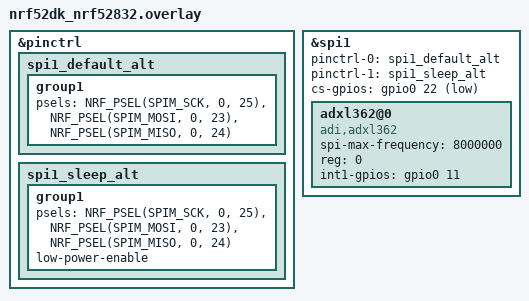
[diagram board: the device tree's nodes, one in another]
/*
 * Copyright (c) 2019 Nordic Semiconductor ASA
 *
 * SPDX-License-Identifier: Apache-2.0
 */

&pinctrl {
	spi1_default_alt: spi1_default_alt {
		group1 {
			psels = <NRF_PSEL(SPIM_SCK, 0, 25)>,
				<NRF_PSEL(SPIM_MOSI, 0, 23)>,
				<NRF_PSEL(SPIM_MISO, 0, 24)>;
		};
	};

	spi1_sleep_alt: spi1_sleep_alt {
		group1 {
			psels = <NRF_PSEL(SPIM_SCK, 0, 25)>,
				<NRF_PSEL(SPIM_MOSI, 0, 23)>,
				<NRF_PSEL(SPIM_MISO, 0, 24)>;
			low-power-enable;
		};
	};
};

&spi1 {
	status = "okay";
	pinctrl-0 = <&spi1_default_alt>;
	pinctrl-1 = <&spi1_sleep_alt>;
	pinctrl-names = "default", "sleep";
	cs-gpios = <&gpio0 22 GPIO_ACTIVE_LOW>;

	adxl362@0 {
		compatible = "adi,adxl362";
		spi-max-frequency = <8000000>;
		reg = <0>;
		int1-gpios = <&gpio0 11 GPIO_ACTIVE_HIGH>;
	};
};
